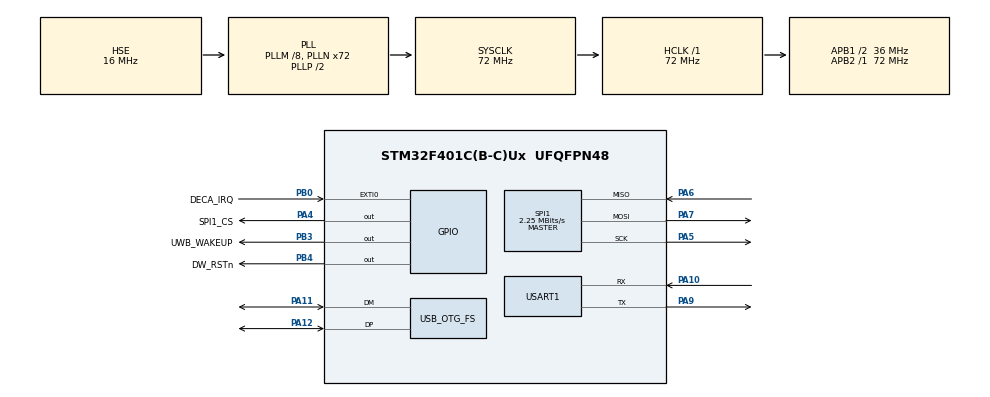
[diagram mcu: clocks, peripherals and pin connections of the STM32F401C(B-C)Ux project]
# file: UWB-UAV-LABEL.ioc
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Mcu.Family=STM32F4
Mcu.Name=STM32F401C(B-C)Ux
Mcu.Package=UFQFPN48
Mcu.UserConstants=LWIP_TIMEVAL_PRIVATE,0
NVIC.EXTI0_IRQn=true\:6\:0\:true\:false\:true\:true\:true\:true
NVIC.OTG_FS_IRQn=true\:5\:0\:true\:false\:true\:false\:true\:true
NVIC.PriorityGroup=NVIC_PRIORITYGROUP_4
NVIC.TIM1_UP_TIM10_IRQn=true\:15\:0\:true\:false\:true\:false\:true\:true
NVIC.TimeBase=TIM1_UP_TIM10_IRQn
NVIC.TimeBaseIP=TIM1
PA10.Mode=Asynchronous
PA10.Signal=USART1_RX
PA11.Mode=Device_Only
PA11.Signal=USB_OTG_FS_DM
PA12.Mode=Device_Only
PA12.Signal=USB_OTG_FS_DP
PA13.Mode=Serial_Wire
PA13.Signal=SYS_JTMS-SWDIO
PA14.Mode=Serial_Wire
PA14.Signal=SYS_JTCK-SWCLK
PA4.GPIO_Label=SPI1_CS
PA4.GPIO_PuPd=GPIO_PULLDOWN
PA4.GPIO_Speed=GPIO_SPEED_FREQ_HIGH
PA4.PinState=GPIO_PIN_SET
PA4.Signal=GPIO_Output
PA5.Mode=Full_Duplex_Master
PA5.Signal=SPI1_SCK
PA6.Mode=Full_Duplex_Master
PA6.Signal=SPI1_MISO
PA7.Mode=Full_Duplex_Master
PA7.Signal=SPI1_MOSI
PA9.Mode=Asynchronous
PA9.Signal=USART1_TX
PB0.GPIO_Label=DECA_IRQ
PB0.Signal=GPXTI0
PB3.GPIO_Label=UWB_WAKEUP
PB3.Signal=GPIO_Output
PB4.GPIO_Label=DW_RSTn
PB4.GPIO_ModeDefaultOutputPP=GPIO_MODE_OUTPUT_OD
PB4.GPIO_PuPd=GPIO_NOPULL
PB4.PinState=GPIO_PIN_SET
PB4.Signal=GPIO_Output
PH0\ -\ OSC_IN.Mode=HSE-External-Oscillator
PH0\ -\ OSC_IN.Signal=RCC_OSC_IN
PH1\ -\ OSC_OUT.Mode=HSE-External-Oscillator
PH1\ -\ OSC_OUT.Signal=RCC_OSC_OUT
ProjectManager.HeapSize=0x200
ProjectManager.StackSize=0x400
ProjectManager.TargetToolchain=STM32CubeIDE
RCC.48MHZClocksFreq_Value=48000000
RCC.AHBFreq_Value=72000000
RCC.APB1CLKDivider=RCC_HCLK_DIV2
RCC.APB1Freq_Value=36000000
RCC.APB1TimFreq_Value=72000000
RCC.APB2Freq_Value=72000000
RCC.APB2TimFreq_Value=72000000
RCC.CortexFreq_Value=72000000
RCC.HCLKFreq_Value=72000000
RCC.HSE_Timout=100
RCC.HSE_VALUE=16000000
RCC.HSI_VALUE=16000000
RCC.LSE_VALUE=32768
RCC.PLLM=8
RCC.PLLN=72
RCC.PLLQ=3
RCC.SYSCLKFreq_VALUE=72000000
RCC.SYSCLKSource=RCC_SYSCLKSOURCE_PLLCLK
RCC.VCOOutputFreq_Value=144000000
SPI1.BaudRatePrescaler=SPI_BAUDRATEPRESCALER_32
SPI1.CRCCalculation=SPI_CRCCALCULATION_DISABLE
SPI1.CalculateBaudRate=2.25 MBits/s
SPI1.Direction=SPI_DIRECTION_2LINES
SPI1.Mode=SPI_MODE_MASTER
SPI1.VirtualType=VM_MASTER
USART1.VirtualMode=VM_ASYNC
USB_DEVICE.CLASS_NAME_FS=CDC
USB_DEVICE.VirtualMode=Cdc
USB_DEVICE.VirtualModeFS=Cdc_FS
USB_OTG_FS.VirtualMode=Device_Only
VP_SYS_VS_tim1.Mode=TIM1
VP_USB_DEVICE_VS_USB_DEVICE_CDC_FS.Mode=CDC_FS
board=custom

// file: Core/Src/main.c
/* USER CODE BEGIN Header */
/**
  ******************************************************************************
  * @file           : main.c
  * @brief          : Main program body
  ******************************************************************************
  * @attention
  *
  * Copyright (c) 2022 STMicroelectronics.
  * All rights reserved.
  *
  * This software is licensed under terms that can be found in the LICENSE file
  * in the root directory of this software component.
  * If no LICENSE file comes with this software, it is provided AS-IS.
  *
  ******************************************************************************
  */
/* USER CODE END Header */
#include "main.h"
#include "spi.h"
#include "usart.h"
#include "usb_device.h"
#include "gpio.h"

/* USER CODE BEGIN Includes */
#include "printf.h"
#include "port.h"
#include "examples_defines.h"

/* USER CODE END Includes */

/* USER CODE BEGIN PV */
extern example_ptr example_pointer;
/* USER CODE END PV */

void SystemClock_Config(void);

int main(void)
{

  /* MCU Configuration--------------------------------------------------------*/

  /* Reset of all peripherals, Initializes the Flash interface and the Systick. */
  HAL_Init();

  /* Configure the system clock */
  SystemClock_Config();

  /* Initialize all configured peripherals */
  MX_GPIO_Init();
  MX_USART1_UART_Init();
  MX_USB_DEVICE_Init();
  MX_SPI1_Init();
  /* USER CODE BEGIN 2 */
  HAL_Delay(1000);
  build_examples();
  port_DisableEXT_IRQ();

//  example_pointer();
  /* USER CODE END 2 */

  /* Infinite loop */
  while (1)
  {

    /* USER CODE BEGIN 3 */
	  example_pointer();
	  HAL_Delay(1000);
  }
  /* USER CODE END 3 */
}

void SystemClock_Config(void)
{
  RCC_OscInitTypeDef RCC_OscInitStruct = {0};
  RCC_ClkInitTypeDef RCC_ClkInitStruct = {0};

  /** Configure the main internal regulator output voltage
  */
  __HAL_RCC_PWR_CLK_ENABLE();
  __HAL_PWR_VOLTAGESCALING_CONFIG(PWR_REGULATOR_VOLTAGE_SCALE2);

  /** Initializes the RCC Oscillators according to the specified parameters
  * in the RCC_OscInitTypeDef structure.
  */
  RCC_OscInitStruct.OscillatorType = RCC_OSCILLATORTYPE_HSE;
  RCC_OscInitStruct.HSEState = RCC_HSE_ON;
  RCC_OscInitStruct.PLL.PLLState = RCC_PLL_ON;
  RCC_OscInitStruct.PLL.PLLSource = RCC_PLLSOURCE_HSE;
  RCC_OscInitStruct.PLL.PLLM = 8;
  RCC_OscInitStruct.PLL.PLLN = 72;
  RCC_OscInitStruct.PLL.PLLP = RCC_PLLP_DIV2;
  RCC_OscInitStruct.PLL.PLLQ = 3;
  if (HAL_RCC_OscConfig(&RCC_OscInitStruct) != HAL_OK)
  {
    Error_Handler();
  }

  /** Initializes the CPU, AHB and APB buses clocks
  */
  RCC_ClkInitStruct.ClockType = RCC_CLOCKTYPE_HCLK|RCC_CLOCKTYPE_SYSCLK
                              |RCC_CLOCKTYPE_PCLK1|RCC_CLOCKTYPE_PCLK2;
  RCC_ClkInitStruct.SYSCLKSource = RCC_SYSCLKSOURCE_PLLCLK;
  RCC_ClkInitStruct.AHBCLKDivider = RCC_SYSCLK_DIV1;
  RCC_ClkInitStruct.APB1CLKDivider = RCC_HCLK_DIV2;
  RCC_ClkInitStruct.APB2CLKDivider = RCC_HCLK_DIV1;

  if (HAL_RCC_ClockConfig(&RCC_ClkInitStruct, FLASH_LATENCY_2) != HAL_OK)
  {
    Error_Handler();
  }
}

void HAL_TIM_PeriodElapsedCallback(TIM_HandleTypeDef *htim)
{
  if (htim->Instance == TIM1) {
    HAL_IncTick();
  }
}

void Error_Handler(void)
{
  __disable_irq();
  while (1)
  {
  }
}
